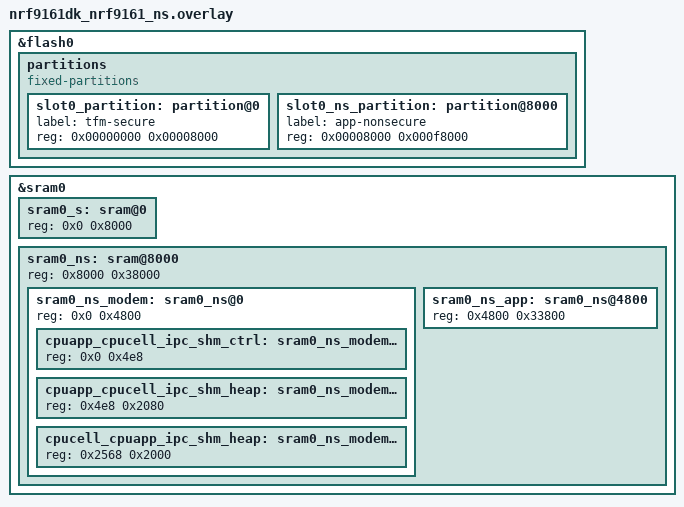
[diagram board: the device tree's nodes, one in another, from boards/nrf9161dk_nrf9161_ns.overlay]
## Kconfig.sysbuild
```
#
# Copyright (c) 2026 Nordic Semiconductor ASA
#
# SPDX-License-Identifier: LicenseRef-Nordic-5-Clause
#

config PARTITION_MANAGER
	default n if !BOARD_THINGY91X

source "share/sysbuild/Kconfig"
```

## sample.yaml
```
sample:
  name: AT Client sample
  description: AT Client sample for cellular devices
tests:
  sample.cellular.at_client:
    sysbuild: true
    build_only: true
    integration_platforms:
      - nrf9151dk/nrf9151/ns
      - nrf9251dk/nrf9251/cpuapp
    platform_allow:
      - nrf9151dk/nrf9151/ns
      - nrf9251dk/nrf9251/cpuapp
      - thingy91x/nrf9151/ns
    tags:
      - ci_build
      - sysbuild
      - ci_samples_cellular
    extra_configs:
      - CONFIG_CLOCK_CONTROL_NRF=n
  sample.cellular.at_client.tracing:
    sysbuild: true
    build_only: true
    integration_platforms:
      - nrf9151dk/nrf9151/ns
    platform_allow:
      - nrf9151dk/nrf9151/ns
      - thingy91x/nrf9151/ns
    tags:
      - ci_build
      - sysbuild
      - ci_samples_cellular
    extra_args:
      - at_client_SNIPPET=nrf91-modem-trace-uart
    extra_configs:
      - CONFIG_CLOCK_CONTROL_NRF=n
  sample.cellular.at_client.legacy:
    sysbuild: true
    build_only: true
    integration_platforms:
      - nrf9151dk/nrf9151/ns
      - nrf9251dk/nrf9251/cpuapp
    platform_allow:
      - nrf9151dk/nrf9151/ns
      - nrf9251dk/nrf9251/cpuapp
      - thingy91x/nrf9151/ns
    tags:
      - ci_build
      - sysbuild
      - ci_samples_cellular
    extra_configs:
      - CONFIG_CLOCK_CONTROL_NRF=y
      - CONFIG_WARN_DEPRECATED=n
  sample.cellular.at_client.tracing.legacy:
    sysbuild: true
    build_only: true
    integration_platforms:
      - nrf9151dk/nrf9151/ns
    platform_allow:
      - nrf9151dk/nrf9151/ns
      - thingy91x/nrf9151/ns
    tags:
      - ci_build
      - sysbuild
      - ci_samples_cellular
    extra_args:
      - at_client_SNIPPET=nrf91-modem-trace-uart
    extra_configs:
      - CONFIG_CLOCK_CONTROL_NRF=y
      - CONFIG_WARN_DEPRECATED=n
```

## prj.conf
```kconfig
#
# Copyright (c) 2019 Nordic Semiconductor ASA
#
# SPDX-License-Identifier: LicenseRef-Nordic-5-Clause
#

# TF-M config
# Ineffective here: no symbol of this choice is available, so selecting one changes nothing.
# CONFIG_TFM_PROFILE_TYPE_MINIMAL=y

# General config
CONFIG_ASSERT=y

# Network
CONFIG_NETWORKING=y
CONFIG_NET_NATIVE=n
CONFIG_NET_SOCKETS=y
CONFIG_NET_SOCKETS_OFFLOAD=y
CONFIG_POSIX_API=y

# Modem library
CONFIG_NRF_MODEM_LIB=y

# AT host library
CONFIG_AT_HOST_LIBRARY=y
CONFIG_UART_INTERRUPT_DRIVEN=y

# Stacks and heaps
CONFIG_MAIN_STACK_SIZE=3072
CONFIG_HEAP_MEM_POOL_SIZE=16384
CONFIG_AT_MONITOR_HEAP_SIZE=512
```

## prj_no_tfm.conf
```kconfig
#
# Copyright (c) 2019 Nordic Semiconductor ASA
#
# SPDX-License-Identifier: LicenseRef-Nordic-5-Clause
#
# Base configuration for targets that build without TF-M, used through
# FILE_SUFFIX=no_tfm.
#
# It differs from prj.conf in the TF-M profile only. The other platforms of this
# sample are non-secure targets where TF-M is part of the build and the minimal
# profile has to be selected, while nrf9251dk builds the application on its own.
# There the TF-M profile choice does not exist, so a single base configuration
# cannot serve both.

# TF-M config
# Ineffective on this target: the TF-M profile choice is only available for the
# non-secure targets that actually build TF-M.
# CONFIG_TFM_PROFILE_TYPE_MINIMAL=y

# General config
CONFIG_ASSERT=y

# Network
CONFIG_NETWORKING=y
CONFIG_NET_NATIVE=n
CONFIG_NET_SOCKETS=y
CONFIG_NET_SOCKETS_OFFLOAD=y
CONFIG_POSIX_API=y

# Modem library
CONFIG_NRF_MODEM_LIB=y

# AT host library
CONFIG_AT_HOST_LIBRARY=y
CONFIG_UART_INTERRUPT_DRIVEN=y

# Stacks and heaps
CONFIG_MAIN_STACK_SIZE=3072
CONFIG_HEAP_MEM_POOL_SIZE=16384
CONFIG_AT_MONITOR_HEAP_SIZE=512
```

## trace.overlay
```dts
/*
 * Copyright (c) 2026 Nordic Semiconductor ASA
 *
 * SPDX-License-Identifier: LicenseRef-Nordic-5-Clause
 */

/* Increase modem (shared) memory. */
&sram0_ns_modem {
	reg = <0x0 0x8800>;
	ranges = <0x0 0x0 0x8800>;

	cpucell_cpuapp_ipc_shm_trace: sram0_ns_modem@4800 {
		/* Modem trace memory */
		reg = <0x4800 0x4000>;
	};
};

/* Delete Non-Secure application memory so we can move it. */
/delete-node/ &sram0_ns_app;

&sram0_ns {
	sram0_ns_app: sram0_ns@8800 {
		/* Redefine smaller Non-Secure application memory. */
		reg = <0x8800 0x2f800>;
	};
};
```

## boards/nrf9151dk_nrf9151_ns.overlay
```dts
/*
 * Copyright (c) 2026 Nordic Semiconductor ASA
 *
 * SPDX-License-Identifier: LicenseRef-Nordic-5-Clause
 */

#include <samples/cellular/nrf91_no_bootloader_partitions.dtsi>

#include <samples/cellular/nrf91_sram_partitions.dtsi>

/ {
	/delete-node/ nordic-tz-secure;
	/delete-node/ nordic-tz-nonsecure;

	nordic-tz-secure {
		compatible = "nordic,tz-secure";
		code-partitions = <&slot0_s_partition>;
	};

	nordic-tz-nonsecure {
		compatible = "nordic,tz-nonsecure";
		code-partitions = <&slot0_ns_partition>;
		data-partitions = <&storage_partition>;
	};
};
```

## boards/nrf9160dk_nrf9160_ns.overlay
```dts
/*
 * Copyright (c) 2026 Nordic Semiconductor ASA
 *
 * SPDX-License-Identifier: LicenseRef-Nordic-5-Clause
 */

#include <samples/cellular/nrf91_no_bootloader_partitions.dtsi>

#include <samples/cellular/nrf91_sram_partitions.dtsi>


/ {
	/delete-node/ nordic-tz-secure;
	/delete-node/ nordic-tz-nonsecure;

	nordic-tz-secure {
		compatible = "nordic,tz-secure";
		code-partitions = <&slot0_s_partition>;
	};

	nordic-tz-nonsecure {
		compatible = "nordic,tz-nonsecure";
		code-partitions = <&slot0_ns_partition>;
		data-partitions = <&storage_partition>;
	};
};
```

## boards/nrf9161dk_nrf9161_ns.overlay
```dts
/*
 * Copyright (c) 2026 Nordic Semiconductor ASA
 *
 * SPDX-License-Identifier: LicenseRef-Nordic-5-Clause
 */

/delete-node/ &boot_partition;
/delete-node/ &slot0_partition;
/delete-node/ &slot1_partition;
/delete-node/ &tfm_ps_partition;
/delete-node/ &tfm_its_partition;
/delete-node/ &tfm_otp_partition;
/delete-node/ &storage_partition;
/delete-node/ &sram0_s;
/delete-node/ &sram0_ns;

&flash0 {
	partitions {
		compatible = "fixed-partitions";
		#address-cells = <1>;
		#size-cells = <1>;

		slot0_partition: partition@0 {
			label = "tfm-secure";
			reg = <0x00000000 0x00008000>;
		};

		slot0_ns_partition: partition@8000 {
			label = "app-nonsecure";
			reg = <0x00008000 0x000f8000>;
		};
	};
};

&sram0 {
	sram0_s: sram@0 {
		/* Secure image memory */
		reg = <0x0 0x8000>;
	};

	sram0_ns: sram@8000 {
		/* Non-Secure image memory */
		reg = <0x8000 0x38000>;
		#address-cells = <1>;
		#size-cells = <1>;
		ranges = <0x0 0x8000 0x38000>;

		sram0_ns_modem: sram0_ns@0 {
			/* Modem (shared) memory */
			reg = <0x0 0x4800>;
			#address-cells = <1>;
			#size-cells = <1>;
			ranges = <0x0 0x0 0x4800>;

			cpuapp_cpucell_ipc_shm_ctrl: sram0_ns_modem@0 {
				/* Modem IPC control */
				reg = <0x0 0x4e8>;
			};

			cpuapp_cpucell_ipc_shm_heap: sram0_ns_modem@4e8 {
				/* Modem IPC transmit */
				reg = <0x4e8 0x2080>;
			};

			cpucell_cpuapp_ipc_shm_heap: sram0_ns_modem@2568 {
				/* Modem IPC receive */
				reg = <0x2568 0x2000>;
			};
		};

		sram0_ns_app: sram0_ns@4800 {
			/* Non-Secure application memory */
			reg = <0x4800 0x33800>;
		};
	};
};
```

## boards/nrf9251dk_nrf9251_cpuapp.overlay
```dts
/*
 * Copyright (c) 2026 Nordic Semiconductor ASA
 *
 * SPDX-License-Identifier: LicenseRef-Nordic-5-Clause
 */

/ {
	chosen {
		ncs,at-host-uart = &uart133;
	};
};
```

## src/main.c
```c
/*
 * Copyright (c) 2018 Nordic Semiconductor ASA
 *
 * SPDX-License-Identifier: LicenseRef-Nordic-5-Clause
 */

#include <zephyr/kernel.h>
#include <stdio.h>
#include <string.h>
#include <modem/nrf_modem_lib.h>
#include <zephyr/drivers/uart.h>
#include <zephyr/drivers/clock_control.h>
#include <zephyr/drivers/clock_control/nrf_clock_control.h>

#if defined(CONFIG_CLOCK_CONTROL_NRF)
/* To strictly comply with UART timing, enable external XTAL oscillator */
void enable_xtal(void)
{
	static struct onoff_client cli = {};

#if defined(CONFIG_CLOCK_CONTROL_NRF)
	struct onoff_manager *clk_mgr;

	clk_mgr = z_nrf_clock_control_get_onoff(CLOCK_CONTROL_NRF_SUBSYS_HF);
	sys_notify_init_spinwait(&cli.notify);
	(void)onoff_request(clk_mgr, &cli);
#else
	const struct device *dev = DEVICE_DT_GET_ONE(COND_CODE_1(NRF_CLOCK_HAS_HFCLK,
							   (nordic_nrf_clock_hfclk),
							   (nordic_nrf_clock_xo)));
	sys_notify_init_spinwait(&cli.notify);
	(void)nrf_clock_control_request(dev, NULL, &cli);
#endif
}
#endif /* CONFIG_CLOCK_CONTROL_NRF */

int main(void)
{
	int err;

	printk("The AT host sample started\n");

	err = nrf_modem_lib_init();
	if (err) {
		printk("Modem library initialization failed, error: %d\n", err);
		return 0;
	}

#if defined(CONFIG_CLOCK_CONTROL_NRF)
	enable_xtal();
#endif /* CONFIG_CLOCK_CONTROL_NRF */

	printk("Ready\n");

	return 0;
}
```
